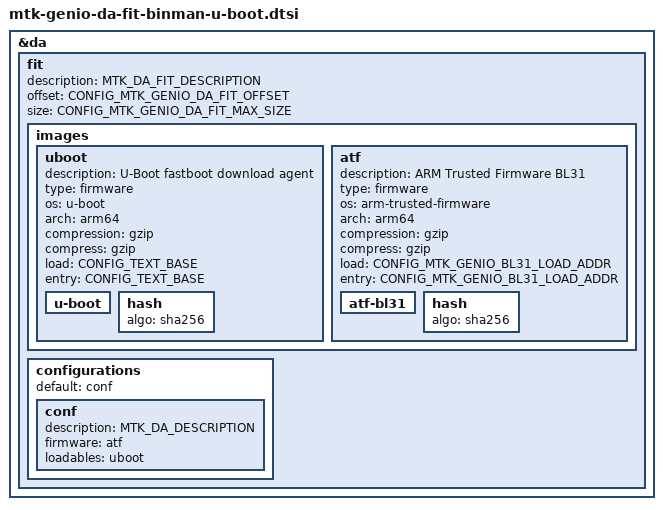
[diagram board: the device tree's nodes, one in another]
// SPDX-License-Identifier: (GPL-2.0-only OR MIT)
/*
 * Copyright (c) 2026 BayLibre, SAS.
 * Author: Carlo Caione <ccaione@baylibre.com>
 */

&da {
	fit {
		description = MTK_DA_FIT_DESCRIPTION;
		offset = <CONFIG_MTK_GENIO_DA_FIT_OFFSET>;
		size = <CONFIG_MTK_GENIO_DA_FIT_MAX_SIZE>;
		#address-cells = <1>;

		images {
			uboot {
				description = "U-Boot fastboot download agent";
				type = "firmware";
				os = "u-boot";
				arch = "arm64";
				compression = "gzip";
				compress = "gzip";
				load = <CONFIG_TEXT_BASE>;
				entry = <CONFIG_TEXT_BASE>;

				u-boot {
				};

				hash {
					algo = "sha256";
				};
			};

			atf {
				description = "ARM Trusted Firmware BL31";
				type = "firmware";
				os = "arm-trusted-firmware";
				arch = "arm64";
				compression = "gzip";
				compress = "gzip";
				load = <CONFIG_MTK_GENIO_BL31_LOAD_ADDR>;
				entry = <CONFIG_MTK_GENIO_BL31_LOAD_ADDR>;

				atf-bl31 {
				};

				hash {
					algo = "sha256";
				};
			};
		};

		configurations {
			default = "conf";

			conf {
				description = MTK_DA_DESCRIPTION;
				firmware = "atf";
				loadables = "uboot";
			};
		};
	};
};
